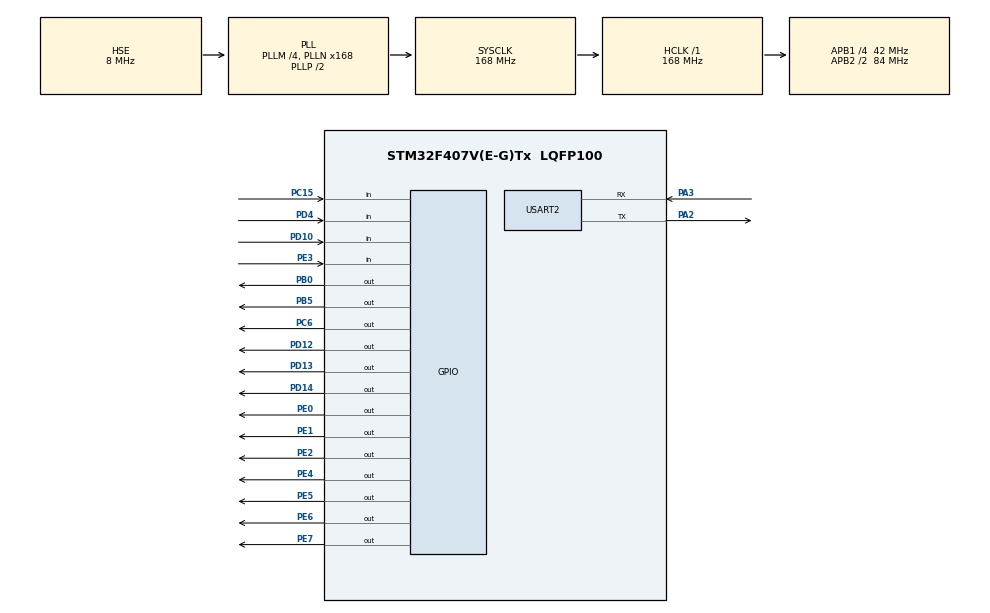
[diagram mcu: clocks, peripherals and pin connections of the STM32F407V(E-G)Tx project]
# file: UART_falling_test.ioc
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Mcu.Family=STM32F4
Mcu.Name=STM32F407V(E-G)Tx
Mcu.Package=LQFP100
NVIC.PriorityGroup=NVIC_PRIORITYGROUP_4
NVIC.TIM7_IRQn=true\:0\:0\:false\:true\:true\:2\:true\:true
NVIC.USART2_IRQn=true\:0\:0\:false\:true\:true\:1\:true\:true
PA2.Mode=Asynchronous
PA2.Signal=USART2_TX
PA3.Mode=Asynchronous
PA3.Signal=USART2_RX
PB0.Signal=GPIO_Output
PB5.Signal=GPIO_Output
PC15-OSC32_OUT.Signal=GPIO_Input
PC6.Signal=GPIO_Output
PD10.Signal=GPIO_Input
PD12.Signal=GPIO_Output
PD13.Signal=GPIO_Output
PD14.Signal=GPIO_Output
PD4.Signal=GPIO_Input
PE0.Signal=GPIO_Output
PE1.Signal=GPIO_Output
PE2.Signal=GPIO_Output
PE3.Signal=GPIO_Input
PE4.Signal=GPIO_Output
PE5.Signal=GPIO_Output
PE6.Signal=GPIO_Output
PE7.Signal=GPIO_Output
PH0-OSC_IN.Mode=HSE-External-Oscillator
PH0-OSC_IN.Signal=RCC_OSC_IN
PH1-OSC_OUT.Mode=HSE-External-Oscillator
PH1-OSC_OUT.Signal=RCC_OSC_OUT
ProjectManager.HeapSize=0x200
ProjectManager.StackSize=0x400
ProjectManager.TargetToolchain=STM32CubeIDE
RCC.48MHZClocksFreq_Value=84000000
RCC.AHBFreq_Value=168000000
RCC.APB1CLKDivider=RCC_HCLK_DIV4
RCC.APB1Freq_Value=42000000
RCC.APB1TimFreq_Value=84000000
RCC.APB2CLKDivider=RCC_HCLK_DIV2
RCC.APB2Freq_Value=84000000
RCC.APB2TimFreq_Value=168000000
RCC.CortexFreq_Value=168000000
RCC.HCLKFreq_Value=168000000
RCC.HSE_VALUE=8000000
RCC.HSI_VALUE=16000000
RCC.LSE_VALUE=32768
RCC.PLLM=4
RCC.PLLN=168
RCC.PLLSourceVirtual=RCC_PLLSOURCE_HSE
RCC.SYSCLKFreq_VALUE=168000000
RCC.SYSCLKSource=RCC_SYSCLKSOURCE_PLLCLK
RCC.VCOOutputFreq_Value=336000000
TIM7.Period=8399
TIM7.Prescaler=9999
USART2.VirtualMode=VM_ASYNC
VP_TIM7_VS_ClockSourceINT.Mode=Enable_Timer
board=custom

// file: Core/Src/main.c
/* USER CODE BEGIN Header */
/**
  ******************************************************************************
  * @file           : main.c
  * @brief          : Main program body
  ******************************************************************************
  * @attention
  *
  * <h2><center>&copy; Copyright (c) 2020 STMicroelectronics.
  * All rights reserved.</center></h2>
  *
  * This software component is licensed by ST under BSD 3-Clause license,
  * the "License"; You may not use this file except in compliance with the
  * License. You may obtain a copy of the License at:
  *                        opensource.org/licenses/BSD-3-Clause
  *
  ******************************************************************************
  */
/* USER CODE END Header */

#include "main.h"

/* USER CODE BEGIN Includes */
#include <stdio.h>
/* USER CODE END Includes */

TIM_HandleTypeDef htim7;

UART_HandleTypeDef huart2;

void SystemClock_Config(void);
static void MX_GPIO_Init(void);
static void MX_USART2_UART_Init(void);
static void MX_TIM7_Init(void);
static void MX_NVIC_Init(void);
/* USER CODE BEGIN PFP */
int _write(int file, char* p, int len)
{
	HAL_UART_Transmit(&huart2,  p, len, 10);
	return len;
}

/* USER CODE END PFP */

int main(void)
{

  /* MCU Configuration--------------------------------------------------------*/

  /* Reset of all peripherals, Initializes the Flash interface and the Systick. */
  HAL_Init();

  /* Configure the system clock */
  SystemClock_Config();

  /* Initialize all configured peripherals */
  MX_GPIO_Init();
  MX_USART2_UART_Init();
  MX_TIM7_Init();

  /* Initialize interrupts */
  MX_NVIC_Init();
  /* USER CODE BEGIN 2 */

  HAL_TIM_Base_Start_IT(&htim7);		// 타이머7 동작 시작
  /* USER CODE END 2 */

  /* Infinite loop */
  /* USER CODE BEGIN WHILE */
  uint8_t a = 0;
  float f = 1.234;
  while (1)
  {
    /* USER CODE END WHILE */

  }
}

void SystemClock_Config(void)
{
  RCC_OscInitTypeDef RCC_OscInitStruct = {0};
  RCC_ClkInitTypeDef RCC_ClkInitStruct = {0};

  /** Configure the main internal regulator output voltage
  */
  __HAL_RCC_PWR_CLK_ENABLE();
  __HAL_PWR_VOLTAGESCALING_CONFIG(PWR_REGULATOR_VOLTAGE_SCALE1);
  /** Initializes the CPU, AHB and APB busses clocks
  */
  RCC_OscInitStruct.OscillatorType = RCC_OSCILLATORTYPE_HSE;
  RCC_OscInitStruct.HSEState = RCC_HSE_ON;
  RCC_OscInitStruct.PLL.PLLState = RCC_PLL_ON;
  RCC_OscInitStruct.PLL.PLLSource = RCC_PLLSOURCE_HSE;
  RCC_OscInitStruct.PLL.PLLM = 4;
  RCC_OscInitStruct.PLL.PLLN = 168;
  RCC_OscInitStruct.PLL.PLLP = RCC_PLLP_DIV2;
  RCC_OscInitStruct.PLL.PLLQ = 4;
  if (HAL_RCC_OscConfig(&RCC_OscInitStruct) != HAL_OK)
  {
    Error_Handler();
  }
  /** Initializes the CPU, AHB and APB busses clocks
  */
  RCC_ClkInitStruct.ClockType = RCC_CLOCKTYPE_HCLK|RCC_CLOCKTYPE_SYSCLK
                              |RCC_CLOCKTYPE_PCLK1|RCC_CLOCKTYPE_PCLK2;
  RCC_ClkInitStruct.SYSCLKSource = RCC_SYSCLKSOURCE_PLLCLK;
  RCC_ClkInitStruct.AHBCLKDivider = RCC_SYSCLK_DIV1;
  RCC_ClkInitStruct.APB1CLKDivider = RCC_HCLK_DIV4;
  RCC_ClkInitStruct.APB2CLKDivider = RCC_HCLK_DIV2;

  if (HAL_RCC_ClockConfig(&RCC_ClkInitStruct, FLASH_LATENCY_5) != HAL_OK)
  {
    Error_Handler();
  }
}

/**
  * @brief NVIC Configuration.
  * @retval None
  */
static void MX_NVIC_Init(void)
{
  /* USART2_IRQn interrupt configuration */
  HAL_NVIC_SetPriority(USART2_IRQn, 0, 0);
  HAL_NVIC_EnableIRQ(USART2_IRQn);
  /* TIM7_IRQn interrupt configuration */
  HAL_NVIC_SetPriority(TIM7_IRQn, 0, 0);
  HAL_NVIC_EnableIRQ(TIM7_IRQn);
}

static void MX_TIM7_Init(void)
{

  TIM_MasterConfigTypeDef sMasterConfig = {0};

  htim7.Instance = TIM7;
  htim7.Init.Prescaler = 9999;
  htim7.Init.CounterMode = TIM_COUNTERMODE_UP;
  htim7.Init.Period = 8399;
  htim7.Init.AutoReloadPreload = TIM_AUTORELOAD_PRELOAD_DISABLE;
  if (HAL_TIM_Base_Init(&htim7) != HAL_OK)
  {
    Error_Handler();
  }
  sMasterConfig.MasterOutputTrigger = TIM_TRGO_RESET;
  sMasterConfig.MasterSlaveMode = TIM_MASTERSLAVEMODE_DISABLE;
  if (HAL_TIMEx_MasterConfigSynchronization(&htim7, &sMasterConfig) != HAL_OK)
  {
    Error_Handler();
  }

}

static void MX_USART2_UART_Init(void)
{

  huart2.Instance = USART2;
  huart2.Init.BaudRate = 115200;
  huart2.Init.WordLength = UART_WORDLENGTH_8B;
  huart2.Init.StopBits = UART_STOPBITS_1;
  huart2.Init.Parity = UART_PARITY_NONE;
  huart2.Init.Mode = UART_MODE_TX_RX;
  huart2.Init.HwFlowCtl = UART_HWCONTROL_NONE;
  huart2.Init.OverSampling = UART_OVERSAMPLING_16;
  if (HAL_UART_Init(&huart2) != HAL_OK)
  {
    Error_Handler();
  }

}

static void MX_GPIO_Init(void)
{
  GPIO_InitTypeDef GPIO_InitStruct = {0};

  /* GPIO Ports Clock Enable */
  __HAL_RCC_GPIOE_CLK_ENABLE();
  __HAL_RCC_GPIOC_CLK_ENABLE();
  __HAL_RCC_GPIOH_CLK_ENABLE();
  __HAL_RCC_GPIOA_CLK_ENABLE();
  __HAL_RCC_GPIOB_CLK_ENABLE();
  __HAL_RCC_GPIOD_CLK_ENABLE();

  /*Configure GPIO pin Output Level */
  HAL_GPIO_WritePin(GPIOE, GPIO_PIN_2|GPIO_PIN_4|GPIO_PIN_5|GPIO_PIN_6
                          |GPIO_PIN_7|GPIO_PIN_0|GPIO_PIN_1, GPIO_PIN_RESET);

  /*Configure GPIO pin Output Level */
  HAL_GPIO_WritePin(GPIOB, GPIO_PIN_0|GPIO_PIN_5, GPIO_PIN_RESET);

  /*Configure GPIO pin Output Level */
  HAL_GPIO_WritePin(GPIOD, GPIO_PIN_12|GPIO_PIN_13|GPIO_PIN_14, GPIO_PIN_RESET);

  /*Configure GPIO pin Output Level */
  HAL_GPIO_WritePin(GPIOC, GPIO_PIN_6, GPIO_PIN_RESET);

  /*Configure GPIO pins : PE2 PE4 PE5 PE6
                           PE7 PE0 PE1 */
  GPIO_InitStruct.Pin = GPIO_PIN_2|GPIO_PIN_4|GPIO_PIN_5|GPIO_PIN_6
                          |GPIO_PIN_7|GPIO_PIN_0|GPIO_PIN_1;
  GPIO_InitStruct.Mode = GPIO_MODE_OUTPUT_PP;
  GPIO_InitStruct.Pull = GPIO_NOPULL;
  GPIO_InitStruct.Speed = GPIO_SPEED_FREQ_LOW;
  HAL_GPIO_Init(GPIOE, &GPIO_InitStruct);

  /*Configure GPIO pin : PE3 */
  GPIO_InitStruct.Pin = GPIO_PIN_3;
  GPIO_InitStruct.Mode = GPIO_MODE_INPUT;
  GPIO_InitStruct.Pull = GPIO_NOPULL;
  HAL_GPIO_Init(GPIOE, &GPIO_InitStruct);

  /*Configure GPIO pin : PC15 */
  GPIO_InitStruct.Pin = GPIO_PIN_15;
  GPIO_InitStruct.Mode = GPIO_MODE_INPUT;
  GPIO_InitStruct.Pull = GPIO_NOPULL;
  HAL_GPIO_Init(GPIOC, &GPIO_InitStruct);

  /*Configure GPIO pins : PB0 PB5 */
  GPIO_InitStruct.Pin = GPIO_PIN_0|GPIO_PIN_5;
  GPIO_InitStruct.Mode = GPIO_MODE_OUTPUT_PP;
  GPIO_InitStruct.Pull = GPIO_NOPULL;
  GPIO_InitStruct.Speed = GPIO_SPEED_FREQ_LOW;
  HAL_GPIO_Init(GPIOB, &GPIO_InitStruct);

  /*Configure GPIO pins : PD10 PD4 */
  GPIO_InitStruct.Pin = GPIO_PIN_10|GPIO_PIN_4;
  GPIO_InitStruct.Mode = GPIO_MODE_INPUT;
  GPIO_InitStruct.Pull = GPIO_NOPULL;
  HAL_GPIO_Init(GPIOD, &GPIO_InitStruct);

  /*Configure GPIO pins : PD12 PD13 PD14 */
  GPIO_InitStruct.Pin = GPIO_PIN_12|GPIO_PIN_13|GPIO_PIN_14;
  GPIO_InitStruct.Mode = GPIO_MODE_OUTPUT_PP;
  GPIO_InitStruct.Pull = GPIO_NOPULL;
  GPIO_InitStruct.Speed = GPIO_SPEED_FREQ_LOW;
  HAL_GPIO_Init(GPIOD, &GPIO_InitStruct);

  /*Configure GPIO pin : PC6 */
  GPIO_InitStruct.Pin = GPIO_PIN_6;
  GPIO_InitStruct.Mode = GPIO_MODE_OUTPUT_PP;
  GPIO_InitStruct.Pull = GPIO_NOPULL;
  GPIO_InitStruct.Speed = GPIO_SPEED_FREQ_LOW;
  HAL_GPIO_Init(GPIOC, &GPIO_InitStruct);

}

/* USER CODE BEGIN 4 */
void HAL_UART_RxCpltCallback(UART_HandleTypeDef *huart)
{
	if(huart->Instance == USART2)
	{
	}
}

void HAL_TIM_PeriodElapsedCallback(TIM_HandleTypeDef *htim)
{
  if(htim->Instance == TIM7)
  {
	  HAL_GPIO_TogglePin(GPIOD, GPIO_PIN_12);		// 1초마다 LED Toggle
  }
}
/* USER CODE END 4 */

void Error_Handler(void)
{
}

/************************ (C) COPYRIGHT STMicroelectronics *****END OF FILE****/
